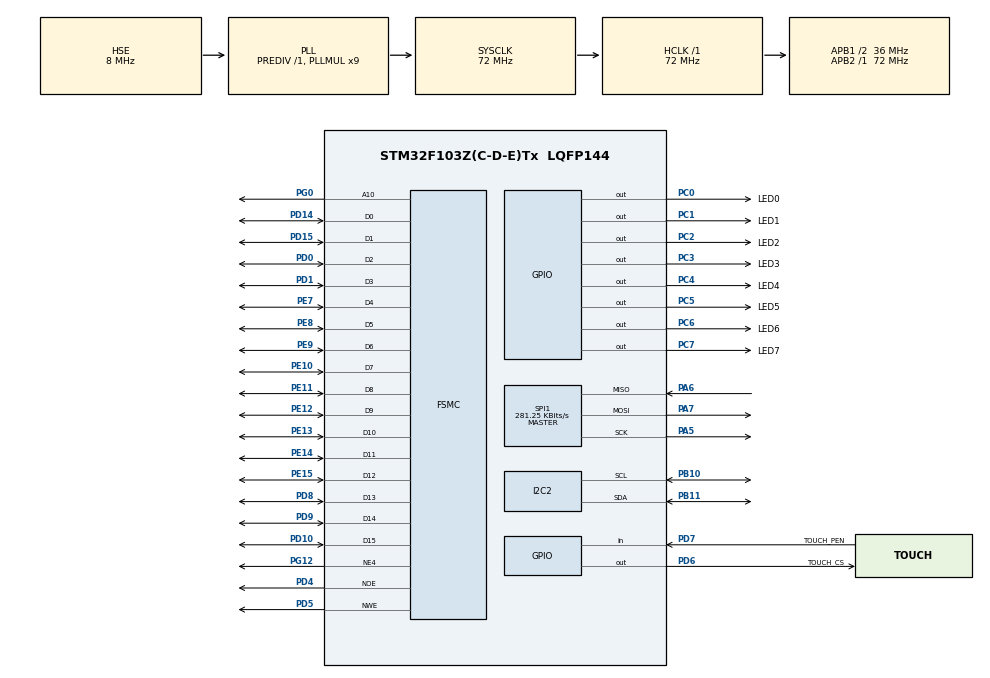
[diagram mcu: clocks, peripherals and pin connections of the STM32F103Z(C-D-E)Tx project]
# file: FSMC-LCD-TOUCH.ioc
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FSMC.AddressSetupTime1=1
FSMC.BusTurnAroundDuration1=0x0
FSMC.DataSetupTime1=1
FSMC.ExtendedMode1=FSMC_EXTENDED_MODE_DISABLE
Mcu.Family=STM32F1
Mcu.Name=STM32F103Z(C-D-E)Tx
Mcu.Package=LQFP144
NVIC.I2C2_ER_IRQn=true\:0\:0\:false\:false\:true\:true\:true
NVIC.I2C2_EV_IRQn=true\:0\:0\:false\:false\:true\:true\:true
NVIC.PriorityGroup=NVIC_PRIORITYGROUP_4
NVIC.TIM2_IRQn=true\:0\:0\:false\:false\:true\:true\:true
OSC_IN.Mode=HSE-External-Oscillator
OSC_IN.Signal=RCC_OSC_IN
OSC_OUT.Mode=HSE-External-Oscillator
OSC_OUT.Signal=RCC_OSC_OUT
PA13.Mode=Serial_Wire
PA13.Signal=SYS_JTMS-SWDIO
PA14.Mode=Serial_Wire
PA14.Signal=SYS_JTCK-SWCLK
PA5.Mode=Full_Duplex_Master
PA5.Signal=SPI1_SCK
PA6.Mode=Full_Duplex_Master
PA6.Signal=SPI1_MISO
PA7.Mode=Full_Duplex_Master
PA7.Signal=SPI1_MOSI
PB10.Mode=I2C
PB10.Signal=I2C2_SCL
PB11.Mode=I2C
PB11.Signal=I2C2_SDA
PC0.GPIO_Label=LED0
PC0.GPIO_ModeDefaultOutputPP=GPIO_MODE_OUTPUT_PP
PC0.GPIO_PuPd=GPIO_NOPULL
PC0.GPIO_Speed=GPIO_SPEED_FREQ_LOW
PC0.PinState=GPIO_PIN_SET
PC0.Signal=GPIO_Output
PC1.GPIO_Label=LED1
PC1.GPIO_ModeDefaultOutputPP=GPIO_MODE_OUTPUT_PP
PC1.GPIO_PuPd=GPIO_NOPULL
PC1.GPIO_Speed=GPIO_SPEED_FREQ_LOW
PC1.PinState=GPIO_PIN_SET
PC1.Signal=GPIO_Output
PC2.GPIO_Label=LED2
PC2.GPIO_ModeDefaultOutputPP=GPIO_MODE_OUTPUT_PP
PC2.GPIO_PuPd=GPIO_NOPULL
PC2.GPIO_Speed=GPIO_SPEED_FREQ_LOW
PC2.PinState=GPIO_PIN_SET
PC2.Signal=GPIO_Output
PC3.GPIO_Label=LED3
PC3.GPIO_ModeDefaultOutputPP=GPIO_MODE_OUTPUT_PP
PC3.GPIO_PuPd=GPIO_NOPULL
PC3.GPIO_Speed=GPIO_SPEED_FREQ_LOW
PC3.PinState=GPIO_PIN_SET
PC3.Signal=GPIO_Output
PC4.GPIO_Label=LED4
PC4.GPIO_ModeDefaultOutputPP=GPIO_MODE_OUTPUT_PP
PC4.GPIO_PuPd=GPIO_NOPULL
PC4.GPIO_Speed=GPIO_SPEED_FREQ_LOW
PC4.PinState=GPIO_PIN_SET
PC4.Signal=GPIO_Output
PC5.GPIO_Label=LED5
PC5.GPIO_ModeDefaultOutputPP=GPIO_MODE_OUTPUT_PP
PC5.GPIO_PuPd=GPIO_NOPULL
PC5.GPIO_Speed=GPIO_SPEED_FREQ_LOW
PC5.PinState=GPIO_PIN_SET
PC5.Signal=GPIO_Output
PC6.GPIO_Label=LED6
PC6.GPIO_ModeDefaultOutputPP=GPIO_MODE_OUTPUT_PP
PC6.GPIO_PuPd=GPIO_NOPULL
PC6.GPIO_Speed=GPIO_SPEED_FREQ_LOW
PC6.PinState=GPIO_PIN_SET
PC6.Signal=GPIO_Output
PC7.GPIO_Label=LED7
PC7.GPIO_ModeDefaultOutputPP=GPIO_MODE_OUTPUT_PP
PC7.GPIO_PuPd=GPIO_NOPULL
PC7.GPIO_Speed=GPIO_SPEED_FREQ_LOW
PC7.PinState=GPIO_PIN_SET
PC7.Signal=GPIO_Output
PD0.Signal=FSMC_D2_DA2
PD1.Signal=FSMC_D3_DA3
PD10.Signal=FSMC_D15_DA15
PD14.Signal=FSMC_D0_DA0
PD15.Signal=FSMC_D1_DA1
PD4.Signal=FSMC_NOE
PD5.Signal=FSMC_NWE
PD6.GPIO_Label=TOUCH_CS
PD6.Signal=GPIO_Output
PD7.GPIO_Label=TOUCH_PEN
PD7.Signal=GPIO_Input
PD8.Signal=FSMC_D13_DA13
PD9.Signal=FSMC_D14_DA14
PE10.Signal=FSMC_D7_DA7
PE11.Signal=FSMC_D8_DA8
PE12.Signal=FSMC_D9_DA9
PE13.Signal=FSMC_D10_DA10
PE14.Signal=FSMC_D11_DA11
PE15.Signal=FSMC_D12_DA12
PE7.Signal=FSMC_D4_DA4
PE8.Signal=FSMC_D5_DA5
PE9.Signal=FSMC_D6_DA6
PG0.Signal=FSMC_A10
PG12.Mode=NorPsramChipSelect4_1
PG12.Signal=FSMC_NE4
ProjectManager.HeapSize=0x200
ProjectManager.StackSize=0x400
ProjectManager.TargetToolchain=MDK-ARM V5.27
RCC.AHBFreq_Value=72000000
RCC.APB1CLKDivider=RCC_HCLK_DIV2
RCC.APB1Freq_Value=36000000
RCC.APB1TimFreq_Value=72000000
RCC.APB2Freq_Value=72000000
RCC.APB2TimFreq_Value=72000000
RCC.HCLKFreq_Value=72000000
RCC.PLLMUL=RCC_PLL_MUL9
RCC.PLLSourceVirtual=RCC_PLLSOURCE_HSE
RCC.SYSCLKFreq_VALUE=72000000
RCC.SYSCLKSource=RCC_SYSCLKSOURCE_PLLCLK
RCC.USBFreq_Value=72000000
SH.FSMC_A10.0=FSMC_A10,A10_1
SH.FSMC_D0_DA0.0=FSMC_D0,16b-d1
SH.FSMC_D10_DA10.0=FSMC_D10,16b-d1
SH.FSMC_D11_DA11.0=FSMC_D11,16b-d1
SH.FSMC_D12_DA12.0=FSMC_D12,16b-d1
SH.FSMC_D13_DA13.0=FSMC_D13,16b-d1
SH.FSMC_D14_DA14.0=FSMC_D14,16b-d1
SH.FSMC_D15_DA15.0=FSMC_D15,16b-d1
SH.FSMC_D1_DA1.0=FSMC_D1,16b-d1
SH.FSMC_D2_DA2.0=FSMC_D2,16b-d1
SH.FSMC_D3_DA3.0=FSMC_D3,16b-d1
SH.FSMC_D4_DA4.0=FSMC_D4,16b-d1
SH.FSMC_D5_DA5.0=FSMC_D5,16b-d1
SH.FSMC_D6_DA6.0=FSMC_D6,16b-d1
SH.FSMC_D7_DA7.0=FSMC_D7,16b-d1
SH.FSMC_D8_DA8.0=FSMC_D8,16b-d1
SH.FSMC_D9_DA9.0=FSMC_D9,16b-d1
SH.FSMC_NOE.0=FSMC_NOE,Lcd1
SH.FSMC_NWE.0=FSMC_NWE,Lcd1
SPI1.BaudRatePrescaler=SPI_BAUDRATEPRESCALER_256
SPI1.CLKPhase=SPI_PHASE_2EDGE
SPI1.CLKPolarity=SPI_POLARITY_HIGH
SPI1.CRCCalculation=SPI_CRCCALCULATION_ENABLE
SPI1.CRCPolynomial=X0+X1+X2
SPI1.CalculateBaudRate=281.25 KBits/s
SPI1.Direction=SPI_DIRECTION_2LINES
SPI1.Mode=SPI_MODE_MASTER
SPI1.VirtualType=VM_MASTER
TIM2.AutoReloadPreload=TIM_AUTORELOAD_PRELOAD_ENABLE
TIM2.Period=10000-1
TIM2.Prescaler=72-1
VP_TIM2_VS_ClockSourceINT.Mode=Internal
board=custom

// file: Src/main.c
/* USER CODE BEGIN Header */
/**
  ******************************************************************************
  * @file           : main.c
  * @brief          : Main program body
  ******************************************************************************
  * @attention
  *
  * <h2><center>&copy; Copyright (c) 2020 STMicroelectronics.
  * All rights reserved.</center></h2>
  *
  * This software component is licensed by ST under BSD 3-Clause license,
  * the "License"; You may not use this file except in compliance with the
  * License. You may obtain a copy of the License at:
  *                        opensource.org/licenses/BSD-3-Clause
  *
  ******************************************************************************
  */
/* USER CODE END Header */

#include "main.h"
#include "i2c.h"
#include "spi.h"
#include "tim.h"
#include "gpio.h"
#include "fsmc.h"

/* USER CODE BEGIN Includes */
#include <string.h>
#include <stdio.h>
#include "tftlcd.h"
#include "touch.h"
/* USER CODE END Includes */

void SystemClock_Config(void);

/* USER CODE BEGIN 0 */
int fputc(int ch, FILE *f)
{
	return ITM_SendChar(ch);
}
/* USER CODE END 0 */

int main(void)
{

  /* MCU Configuration--------------------------------------------------------*/

  /* Reset of all peripherals, Initializes the Flash interface and the Systick. */
  HAL_Init();

  /* Configure the system clock */
  SystemClock_Config();

  /* Initialize all configured peripherals */
  MX_GPIO_Init();
  MX_FSMC_Init();
  MX_TIM2_Init();
  MX_SPI1_Init();
  MX_I2C2_Init();
  /* USER CODE BEGIN 2 */
	HAL_LCD_Init();
	HAL_TOUCH_Init();

  /* USER CODE END 2 */

  /* Infinite loop */
  while (1)
  {

    /* USER CODE BEGIN 3 */

		if(HAL_TOUCH_Scan() == 0)
		{
			printf("touch ok\n");
		}
		else
		{
		//	printf("not touch error\n");
		}
  }
  /* USER CODE END 3 */
}

void SystemClock_Config(void)
{
  RCC_OscInitTypeDef RCC_OscInitStruct = {0};
  RCC_ClkInitTypeDef RCC_ClkInitStruct = {0};

  /** Initializes the CPU, AHB and APB busses clocks
  */
  RCC_OscInitStruct.OscillatorType = RCC_OSCILLATORTYPE_HSE;
  RCC_OscInitStruct.HSEState = RCC_HSE_ON;
  RCC_OscInitStruct.HSEPredivValue = RCC_HSE_PREDIV_DIV1;
  RCC_OscInitStruct.HSIState = RCC_HSI_ON;
  RCC_OscInitStruct.PLL.PLLState = RCC_PLL_ON;
  RCC_OscInitStruct.PLL.PLLSource = RCC_PLLSOURCE_HSE;
  RCC_OscInitStruct.PLL.PLLMUL = RCC_PLL_MUL9;
  if (HAL_RCC_OscConfig(&RCC_OscInitStruct) != HAL_OK)
  {
    Error_Handler();
  }
  /** Initializes the CPU, AHB and APB busses clocks
  */
  RCC_ClkInitStruct.ClockType = RCC_CLOCKTYPE_HCLK|RCC_CLOCKTYPE_SYSCLK
                              |RCC_CLOCKTYPE_PCLK1|RCC_CLOCKTYPE_PCLK2;
  RCC_ClkInitStruct.SYSCLKSource = RCC_SYSCLKSOURCE_PLLCLK;
  RCC_ClkInitStruct.AHBCLKDivider = RCC_SYSCLK_DIV1;
  RCC_ClkInitStruct.APB1CLKDivider = RCC_HCLK_DIV2;
  RCC_ClkInitStruct.APB2CLKDivider = RCC_HCLK_DIV1;

  if (HAL_RCC_ClockConfig(&RCC_ClkInitStruct, FLASH_LATENCY_2) != HAL_OK)
  {
    Error_Handler();
  }
}

void Error_Handler(void)
{
}

/************************ (C) COPYRIGHT STMicroelectronics *****END OF FILE****/
